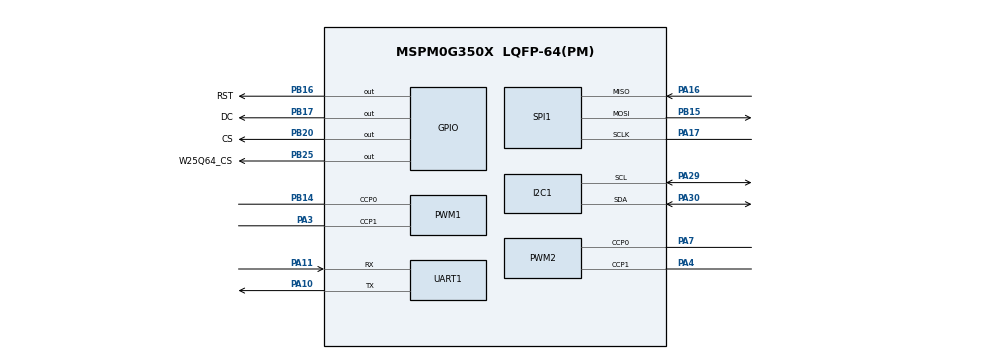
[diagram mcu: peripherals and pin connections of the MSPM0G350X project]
/**
 * @cliArgs --device "MSPM0G350X" --part "Default" --package "LQFP-64(PM)" --product "mspm0_sdk@2.04.00.06"
 * @versions {"tool":"1.23.1+4034"}
 */

/**
 * Import the modules used in this configuration.
 */
const Board         = scripting.addModule("/ti/driverlib/Board");
const GPIO          = scripting.addModule("/ti/driverlib/GPIO", {}, false);
const GPIO1         = GPIO.addInstance();
const GPIO2         = GPIO.addInstance();
const GPIO3         = GPIO.addInstance();
const GPIO4         = GPIO.addInstance();
const I2C           = scripting.addModule("/ti/driverlib/I2C", {}, false);
const I2C1          = I2C.addInstance();
const PWM           = scripting.addModule("/ti/driverlib/PWM", {}, false);
const PWM1          = PWM.addInstance();
const PWM2          = PWM.addInstance();
const SPI           = scripting.addModule("/ti/driverlib/SPI", {}, false);
const SPI1          = SPI.addInstance();
const SYSCTL        = scripting.addModule("/ti/driverlib/SYSCTL");
const TIMER         = scripting.addModule("/ti/driverlib/TIMER", {}, false);
const TIMER1        = TIMER.addInstance();
const UART          = scripting.addModule("/ti/driverlib/UART", {}, false);
const UART1         = UART.addInstance();
const ProjectConfig = scripting.addModule("/ti/project_config/ProjectConfig");

/**
 * Write custom configuration values to the imported modules.
 */

GPIO1.$name                          = "PCA9555";
GPIO1.associatedPins.create(2);
GPIO1.associatedPins[0].assignedPort = "PORTA";
GPIO1.associatedPins[0].assignedPin  = "0";
GPIO1.associatedPins[0].$name        = "SCL1";
GPIO1.associatedPins[1].assignedPort = "PORTA";
GPIO1.associatedPins[1].assignedPin  = "1";
GPIO1.associatedPins[1].$name        = "SDA1";

GPIO2.$name                               = "OLED";
GPIO2.associatedPins.create(2);
GPIO2.associatedPins[0].$name             = "SCL2";
GPIO2.associatedPins[0].assignedPort      = "PORTB";
GPIO2.associatedPins[0].assignedPin       = "2";
GPIO2.associatedPins[0].direction         = "INPUT";
GPIO2.associatedPins[0].polarity          = "RISE_FALL";
GPIO2.associatedPins[0].interruptPriority = "2";
GPIO2.associatedPins[1].$name             = "SDA2";
GPIO2.associatedPins[1].assignedPort      = "PORTB";
GPIO2.associatedPins[1].assignedPin       = "3";

GPIO3.$name                              = "PORTB";
GPIO3.associatedPins.create(4);
GPIO3.associatedPins[0].$name            = "RST";
GPIO3.associatedPins[0].pin.$assign      = "PB16";
GPIO3.associatedPins[1].$name            = "DC";
GPIO3.associatedPins[1].pin.$assign      = "PB17";
GPIO3.associatedPins[2].$name            = "CS";
GPIO3.associatedPins[2].pin.$assign      = "PB20";
GPIO3.associatedPins[3].$name            = "W25Q64_CS";
GPIO3.associatedPins[3].initialValue     = "SET";
GPIO3.associatedPins[3].internalResistor = "PULL_UP";
GPIO3.associatedPins[3].pin.$assign      = "PB25";

GPIO4.port                                = "PORTB";
GPIO4.$name                               = "ENCODER";
GPIO4.associatedPins.create(4);
GPIO4.associatedPins[0].direction         = "INPUT";
GPIO4.associatedPins[0].polarity          = "RISE_FALL";
GPIO4.associatedPins[0].interruptPriority = "2";
GPIO4.associatedPins[0].$name             = "D1";
GPIO4.associatedPins[0].assignedPin       = "6";
GPIO4.associatedPins[1].$name             = "D2";
GPIO4.associatedPins[1].assignedPin       = "7";
GPIO4.associatedPins[1].direction         = "INPUT";
GPIO4.associatedPins[2].$name             = "P1";
GPIO4.associatedPins[2].assignedPin       = "4";
GPIO4.associatedPins[2].direction         = "INPUT";
GPIO4.associatedPins[2].interruptEn       = true;
GPIO4.associatedPins[2].polarity          = "RISE";
GPIO4.associatedPins[3].$name             = "P2";
GPIO4.associatedPins[3].assignedPin       = "5";
GPIO4.associatedPins[3].direction         = "INPUT";
GPIO4.associatedPins[3].interruptEn       = true;
GPIO4.associatedPins[3].polarity          = "RISE";

I2C1.$name                           = "I2C_0";
I2C1.basicEnableController           = true;
I2C1.basicControllerStandardBusSpeed = "FastPlus";
I2C1.peripheral.$assign              = "I2C1";
I2C1.peripheral.sdaPin.$assign       = "PA30";
I2C1.peripheral.sclPin.$assign       = "PA29";
I2C1.sdaPinConfig.$name              = "ti_driverlib_gpio_GPIOPinGeneric9";
I2C1.sclPinConfig.$name              = "ti_driverlib_gpio_GPIOPinGeneric10";

PWM1.$name                              = "Motor_PWM1";
PWM1.timerStartTimer                    = true;
PWM1.pwmMode                            = "EDGE_ALIGN_UP";
PWM1.timerCount                         = 3000;
PWM1.clockDivider                       = 8;
PWM1.peripheral.$assign                 = "TIMA0";
PWM1.peripheral.ccp0Pin.$assign         = "PB14";
PWM1.peripheral.ccp1Pin.$assign         = "PA3";
PWM1.PWM_CHANNEL_0.$name                = "ti_driverlib_pwm_PWMTimerCC0";
PWM1.PWM_CHANNEL_1.$name                = "ti_driverlib_pwm_PWMTimerCC1";
PWM1.ccp0PinConfig.direction            = scripting.forceWrite("OUTPUT");
PWM1.ccp0PinConfig.hideOutputInversion  = scripting.forceWrite(false);
PWM1.ccp0PinConfig.onlyInternalResistor = scripting.forceWrite(false);
PWM1.ccp0PinConfig.passedPeripheralType = scripting.forceWrite("Digital");
PWM1.ccp0PinConfig.$name                = "ti_driverlib_gpio_GPIOPinGeneric0";
PWM1.ccp1PinConfig.direction            = scripting.forceWrite("OUTPUT");
PWM1.ccp1PinConfig.hideOutputInversion  = scripting.forceWrite(false);
PWM1.ccp1PinConfig.onlyInternalResistor = scripting.forceWrite(false);
PWM1.ccp1PinConfig.passedPeripheralType = scripting.forceWrite("Digital");
PWM1.ccp1PinConfig.$name                = "ti_driverlib_gpio_GPIOPinGeneric1";

PWM2.timerCount                         = 3000;
PWM2.clockDivider                       = 8;
PWM2.$name                              = "Motor_PWM2";
PWM2.timerStartTimer                    = true;
PWM2.pwmMode                            = "EDGE_ALIGN_UP";
PWM2.peripheral.$assign                 = "TIMG8";
PWM2.peripheral.ccp0Pin.$assign         = "PA7";
PWM2.peripheral.ccp1Pin.$assign         = "PA4";
PWM2.PWM_CHANNEL_0.$name                = "ti_driverlib_pwm_PWMTimerCC2";
PWM2.PWM_CHANNEL_1.$name                = "ti_driverlib_pwm_PWMTimerCC3";
PWM2.ccp0PinConfig.direction            = scripting.forceWrite("OUTPUT");
PWM2.ccp0PinConfig.hideOutputInversion  = scripting.forceWrite(false);
PWM2.ccp0PinConfig.onlyInternalResistor = scripting.forceWrite(false);
PWM2.ccp0PinConfig.passedPeripheralType = scripting.forceWrite("Digital");
PWM2.ccp0PinConfig.$name                = "ti_driverlib_gpio_GPIOPinGeneric2";
PWM2.ccp1PinConfig.direction            = scripting.forceWrite("OUTPUT");
PWM2.ccp1PinConfig.hideOutputInversion  = scripting.forceWrite(false);
PWM2.ccp1PinConfig.onlyInternalResistor = scripting.forceWrite(false);
PWM2.ccp1PinConfig.passedPeripheralType = scripting.forceWrite("Digital");
PWM2.ccp1PinConfig.$name                = "ti_driverlib_gpio_GPIOPinGeneric3";

SPI1.$name                      = "SPI_0";
SPI1.targetBitRate              = 1000000;
SPI1.frameFormat                = "MOTO3";
SPI1.phase                      = "1";
SPI1.polarity                   = "1";
SPI1.sclkPinConfig.$name        = "ti_driverlib_gpio_GPIOPinGeneric4";
SPI1.mosiPinConfig.$name        = "ti_driverlib_gpio_GPIOPinGeneric5";
SPI1.misoPinConfig.$name        = "ti_driverlib_gpio_GPIOPinGeneric6";
SPI1.peripheral.$assign         = "SPI1";
SPI1.peripheral.sclkPin.$assign = "PA17";
SPI1.peripheral.mosiPin.$assign = "PB15";
SPI1.peripheral.misoPin.$assign = "PA16";

SYSCTL.clockTreeEn = true;

TIMER1.$name              = "TIMER_delay";
TIMER1.timerClkDiv        = 8;
TIMER1.interrupts         = ["ZERO"];
TIMER1.timerPeriod        = "0.01ms";
TIMER1.timerClkPrescale   = 99;
TIMER1.peripheral.$assign = "TIMA1";

UART1.$name                            = "UART_DEBUG";
UART1.targetBaudRate                   = 115200;
UART1.peripheral.$assign               = "UART0";
UART1.peripheral.rxPin.$assign         = "PA11";
UART1.peripheral.txPin.$assign         = "PA10";
UART1.txPinConfig.direction            = scripting.forceWrite("OUTPUT");
UART1.txPinConfig.hideOutputInversion  = scripting.forceWrite(false);
UART1.txPinConfig.onlyInternalResistor = scripting.forceWrite(false);
UART1.txPinConfig.passedPeripheralType = scripting.forceWrite("Digital");
UART1.txPinConfig.$name                = "ti_driverlib_gpio_GPIOPinGeneric7";
UART1.rxPinConfig.hideOutputInversion  = scripting.forceWrite(false);
UART1.rxPinConfig.onlyInternalResistor = scripting.forceWrite(false);
UART1.rxPinConfig.passedPeripheralType = scripting.forceWrite("Digital");
UART1.rxPinConfig.$name                = "ti_driverlib_gpio_GPIOPinGeneric8";

ProjectConfig.genDisable = true;
scripting.suppress("Project Configuration File generation is disabled for this project\\. SysConfig Project Migration is not currently supported for this project\\.", ProjectConfig);

/**
 * Pinmux solution for unlocked pins/peripherals. This ensures that minor changes to the automatic solver in a future
 * version of the tool will not impact the pinmux you originally saw.  These lines can be completely deleted in order to
 * re-solve from scratch.
 */
Board.peripheral.$suggestSolution            = "DEBUGSS";
Board.peripheral.swclkPin.$suggestSolution   = "PA20";
Board.peripheral.swdioPin.$suggestSolution   = "PA19";
GPIO1.associatedPins[0].pin.$suggestSolution = "PA0";
GPIO1.associatedPins[1].pin.$suggestSolution = "PA1";
GPIO2.associatedPins[0].pin.$suggestSolution = "PB2";
GPIO2.associatedPins[1].pin.$suggestSolution = "PB3";
GPIO4.associatedPins[0].pin.$suggestSolution = "PB6";
GPIO4.associatedPins[1].pin.$suggestSolution = "PB7";
GPIO4.associatedPins[2].pin.$suggestSolution = "PB4";
GPIO4.associatedPins[3].pin.$suggestSolution = "PB5";
